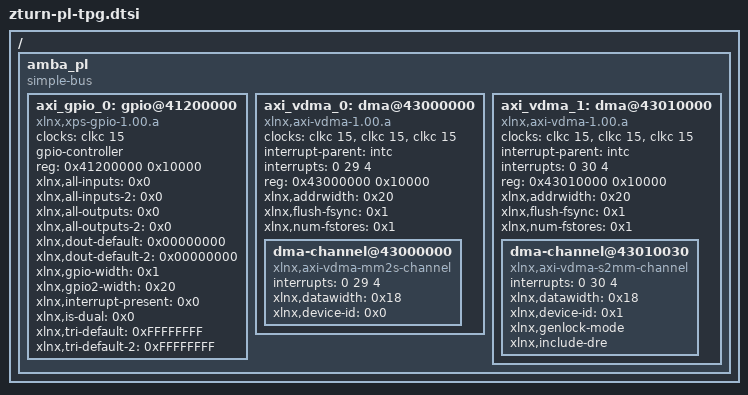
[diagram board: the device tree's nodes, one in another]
/*
 * CAUTION: This file is automatically generated by Xilinx.
 * Version:  
 * Today is: Tue Dec  4 14:12:57 2018
 */


/ {
	amba_pl: amba_pl {
		#address-cells = <1>;
		#size-cells = <1>;
		compatible = "simple-bus";
		ranges ;
		axi_gpio_0: gpio@41200000 {
			#gpio-cells = <3>;
			clock-names = "s_axi_aclk";
			clocks = <&clkc 15>;
			compatible = "xlnx,xps-gpio-1.00.a";
			gpio-controller ;
			reg = <0x41200000 0x10000>;
			xlnx,all-inputs = <0x0>;
			xlnx,all-inputs-2 = <0x0>;
			xlnx,all-outputs = <0x0>;
			xlnx,all-outputs-2 = <0x0>;
			xlnx,dout-default = <0x00000000>;
			xlnx,dout-default-2 = <0x00000000>;
			xlnx,gpio-width = <0x1>;
			xlnx,gpio2-width = <0x20>;
			xlnx,interrupt-present = <0x0>;
			xlnx,is-dual = <0x0>;
			xlnx,tri-default = <0xFFFFFFFF>;
			xlnx,tri-default-2 = <0xFFFFFFFF>;
		};
		axi_vdma_0: dma@43000000 {
			#dma-cells = <1>;
			clock-names = "s_axi_lite_aclk", "m_axi_mm2s_aclk", "m_axi_mm2s_aclk";
			clocks = <&clkc 15>, <&clkc 15>, <&clkc 15>;
			compatible = "xlnx,axi-vdma-1.00.a";
			interrupt-names = "mm2s_introut";
			interrupt-parent = <&intc>;
			interrupts = <0 29 4>;
			reg = <0x43000000 0x10000>;
			xlnx,addrwidth = <0x20>;
			xlnx,flush-fsync = <0x1>;
			xlnx,num-fstores = <0x1>;
			dma-channel@43000000 {
				compatible = "xlnx,axi-vdma-mm2s-channel";
				interrupts = <0 29 4>;
				xlnx,datawidth = <0x18>;
				xlnx,device-id = <0x0>;
			};
		};
		axi_vdma_1: dma@43010000 {
			#dma-cells = <1>;
			clock-names = "s_axi_lite_aclk", "m_axi_s2mm_aclk", "m_axi_s2mm_aclk";
			clocks = <&clkc 15>, <&clkc 15>, <&clkc 15>;
			compatible = "xlnx,axi-vdma-1.00.a";
			interrupt-names = "s2mm_introut";
			interrupt-parent = <&intc>;
			interrupts = <0 30 4>;
			reg = <0x43010000 0x10000>;
			xlnx,addrwidth = <0x20>;
			xlnx,flush-fsync = <0x1>;
			xlnx,num-fstores = <0x1>;
			dma-channel@43010030 {
				compatible = "xlnx,axi-vdma-s2mm-channel";
				interrupts = <0 30 4>;
				xlnx,datawidth = <0x18>;
				xlnx,device-id = <0x1>;
				xlnx,genlock-mode ;
				xlnx,include-dre ;
			};
		};
		
		// v_tpg_0: v_tpg@43c00000 {
		// 	compatible = "xlnx,v-tpg-7.0";
		// 	reg = <0x43c00000 0x10000>;

		// 	clocks = <&clkc 15>;

		// 	reset-gpios = <&gpio0 54 1>;

        //     ports {
        //         #address-cells = <1>;
        //         #size-cells = <0>;

		// 		port@0 {
        //             reg = <0>;

        //             xlnx,video-format = <2>;
        //             xlnx,video-width = <8>;

        //             tpg_out: endpoint {
        //                 remote-endpoint = <&vcap_in>;
        //             };
        //         };
        //     };
		// };
	};
};
